# PIC32CX2051MTSH128S1 device description
Architecture: CORTEX-M4; Family: PIC32CXMT; Series: PIC32CXMTSH
Registers are 32-bit, read-write, no defined reset value unless marked. A register's access mark holds for its fields unless they carry their own. Offsets are from the block's base; [hi:lo] are bit positions.

## UART — Universal Asynchronous Receiver Transmitter
Instances: UART 0x48010000
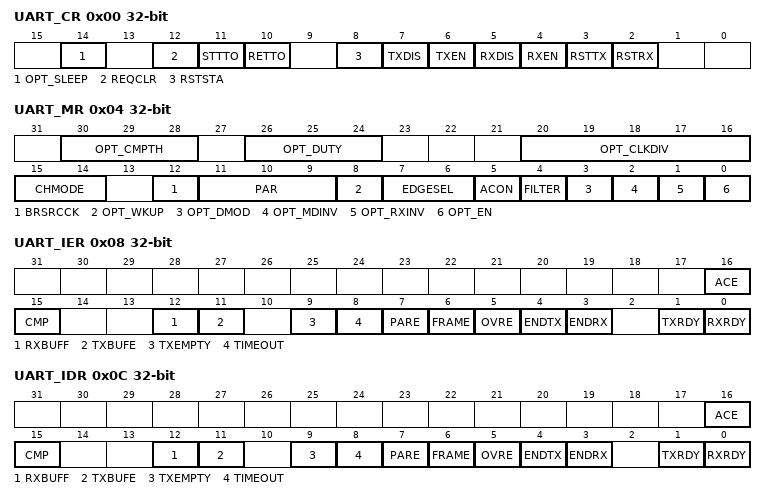
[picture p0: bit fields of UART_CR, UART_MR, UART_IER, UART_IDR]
0x00 UART_CR wo — Control Register
  [14] OPT_SLEEP — Optical Logic Sleep Mode Command
  [12] REQCLR — Request Clear
  [11] STTTO — Start Time-out
  [10] RETTO — Rearm Time-out
  [8] RSTSTA — Reset Status
  [7] TXDIS — Transmitter Disable
  [6] TXEN — Transmitter Enable
  [5] RXDIS — Receiver Disable
  [4] RXEN — Receiver Enable
  [3] RSTTX — Reset Transmitter
  [2] RSTRX — Reset Receiver
0x04 UART_MR — Mode Register
  [30:28] OPT_CMPTH — Receive Path Comparator Threshold
    0=VDD3V3_DIV2 (Comparator threshold is VDD3V3/2 volts.); 1=VDD3V3_DIV2P5 (Comparator threshold is VDD3V3/2.5 volts.); 2=VDD3V3_DIV3P3 (Comparator threshold is VDD3V3/3.3 volts.); 3=VDD3V3_DIV5 (Comparator threshold is VDD3V3/5 volts.); 4=VDD3V3_DIV10 (Comparator threshold is VDD3V3/10 volts.)
  [26:24] OPT_DUTY — Optical Link Modulation Clock Duty Cycle
    0=DUTY_50 (Modulation clock duty cycle Is 50%.); 1=DUTY_43P75 (Modulation clock duty cycle Is 43.75%.); 2=DUTY_37P5 (Modulation clock duty cycle Is 37.5%.); 3=DUTY_31P25 (Modulation clock duty cycle Is 31.75%.); 4=DUTY_25 (Modulation clock duty cycle Is 25%.); 5=DUTY_18P75 (Modulation clock duty cycle Is 18.75%.); 6=DUTY_12P5 (Modulation clock duty cycle Is 12.5%.); 7=DUTY_6P25 (Modulation clock duty cycle Is 6.25%.)
  [20:16] OPT_CLKDIV — Optical Link Clock Divider
  [15:14] CHMODE — Channel Mode
    0=NORMAL (Normal mode); 1=AUTOMATIC (Automatic echo); 2=LOCAL_LOOPBACK; 3=REMOTE_LOOPBACK
  [12] BRSRCCK — Baud Rate Source Clock
    0=PERIPH_CLK (The baud rate is driven by the peripheral clock); 1=GCLK (The baud rate is driven by a PMC-programmable clock GCLK (see the section "Power Management Controller (PMC)").)
  [11:9] PAR — Parity Type
    0=EVEN (Even Parity); 1=ODD (Odd Parity); 2=SPACE (Space: parity forced to 0); 3=MARK (Mark: parity forced to 1); 4=NO (No parity)
  [8] OPT_WKUP — Optical Link Activity Wake-up Enable
    0=DISABLED (To detect any activity on the output of analog comparator, the clock is always active and OPT_EN must be written to 1..); 1=ENABLED (If OPT_EN=0 and a logical 1 is detected after inversion (if RXINV=1) on analog comparator output, the clock if automatically enabled for all UART sub-modules. After a period of inactivity on URXD (time-out) the software can instruct the UART to disabled the clock of all sub-modules to reduce power consumption by applying the UART_CR.OPT_SLEEP command.)
  [7:6] EDGESEL — Analog Comparator Output Edge Selection
    0=RISING (The UART_SR.ACE is set if a rising edge is detected on analog comparator output.); 1=FALLING (The UART_SR.ACE is set if a falling edge is detected on analog comparator output.); 2=ANY_EDGE (The UART_SR.ACE is set as soon as an edge is detected on analog comparator output.)
  [5] ACON — Analog Comparator Enable
    0=DISABLED (The analog comparator is disabled. If OPT_EN=1, the analog comparator is enabled.); 1=ENABLED (The analog comparator is enabled.)
  [4] FILTER — Receiver Digital Filter
    0=DISABLED (UART does not filter the receive line.); 1=ENABLED (UART filters the receive line using a three-sample filter (16x-bit clock) (2 over 3 majority).)
  [3] OPT_DMOD — Optical Demodulation Enable
    0=DISABLED (The optical demodulator is disabled. External demodulation must be enabled.); 1=ENABLED (The optical demodulator is enabled.)
  [2] OPT_MDINV — UART Modulated Data Inverted
    0=DISABLED (The output of the modulator is not inverted.); 1=ENABLED (The output of the modulator is inverted.)
  [1] OPT_RXINV — UART Receive Data Inverted
    0=DISABLED (The comparator data output is not inverted before entering UART.); 1=ENABLED (The comparator data output is inverted before entering UART.)
  [0] OPT_EN — UART Optical Interface Enable
    0=DISABLED (Disables the UART optical link.); 1=ENABLED (Enables the UART optical link.)
0x08 UART_IER wo — Interrupt Enable Register
  [16] ACE — Enable Analog Comparator Event Interrupt
  [15] CMP — Enable Comparison Interrupt
  [12] RXBUFF — Enable Buffer Full Interrupt
  [11] TXBUFE — Enable Buffer Empty Interrupt
  [9] TXEMPTY — Enable TXEMPTY Interrupt
  [8] TIMEOUT — Enable Time-out Interrupt
  [7] PARE — Enable Parity Error Interrupt
  [6] FRAME — Enable Framing Error Interrupt
  [5] OVRE — Enable Overrun Error Interrupt
  [4] ENDTX — Enable End of Transmit Interrupt
  [3] ENDRX — Enable End of Receive Transfer Interrupt
  [1] TXRDY — Enable TXRDY Interrupt
  [0] RXRDY — Enable RXRDY Interrupt
0x0C UART_IDR wo — Interrupt Disable Register
  [16] ACE — Disable Analog Comparator Event Interrupt
  [15] CMP — Disable Comparison Interrupt
  [12] RXBUFF — Disable Buffer Full Interrupt
  [11] TXBUFE — Disable Buffer Empty Interrupt
  [9] TXEMPTY — Disable TXEMPTY Interrupt
  [8] TIMEOUT — Disable Time-out Interrupt
  [7] PARE — Disable Parity Error Interrupt
  [6] FRAME — Disable Framing Error Interrupt
  [5] OVRE — Disable Overrun Error Interrupt
  [4] ENDTX — Disable End of Transmit Interrupt
  [3] ENDRX — Disable End of Receive Transfer Interrupt
  [1] TXRDY — Disable TXRDY Interrupt
  [0] RXRDY — Disable RXRDY Interrupt
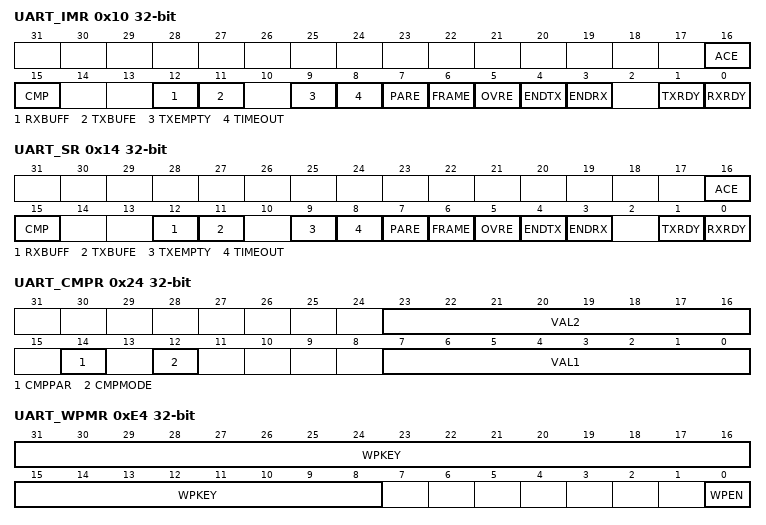
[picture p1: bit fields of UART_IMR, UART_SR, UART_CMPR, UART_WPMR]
0x10 UART_IMR ro — Interrupt Mask Register
  [16] ACE — Mask Analog Comparator Event Interrupt
  [15] CMP — Mask Comparison Interrupt
  [12] RXBUFF — Mask RXBUFF Interrupt
  [11] TXBUFE — Mask TXBUFE Interrupt
  [9] TXEMPTY — Mask TXEMPTY Interrupt
  [8] TIMEOUT — Mask Time-out Interrupt
  [7] PARE — Mask Parity Error Interrupt
  [6] FRAME — Mask Framing Error Interrupt
  [5] OVRE — Mask Overrun Error Interrupt
  [4] ENDTX — Mask End of Transmit Interrupt
  [3] ENDRX — Mask End of Receive Transfer Interrupt
  [1] TXRDY — Mask TXRDY Interrupt
  [0] RXRDY — Mask RXRDY Interrupt
0x14 UART_SR ro — Interrupt Status Register
  [16] ACE — Analog Comparator Event Interrupt (Cleared by writing UART_CR.RSTSTA)
  [15] CMP — Comparison Match (Cleared by writing the UART_CR.RSTSTA)
  [12] RXBUFF — Receive Buffer Full
  [11] TXBUFE — Transmission Buffer Empty
  [9] TXEMPTY — Transmitter Empty (Cleared by writing the UART_THR)
  [8] TIMEOUT — Receiver Time-out (Cleared by writing the UART_CR.STTTO)
  [7] PARE — Parity Error (Cleared by writing UART_CR.RSTSTA)
  [6] FRAME — Framing Error (Cleared by writing UART_CR.RSTSTA)
  [5] OVRE — Overrun Error (Cleared by writing UART_CR.RSTSTA)
  [4] ENDTX — End of Transmitter Transfer
  [3] ENDRX — End of Receiver Transfer
  [1] TXRDY — Transmitter Ready (Cleared by writing the UART_THR)
  [0] RXRDY — Receiver Ready (Cleared by reading the UART_RHR)
0x18 UART_RHR ro — Receive Holding Register
  [7:0] RXCHR — Received Character
0x1C UART_THR wo — Transmit Holding Register
  [7:0] TXCHR — Character to be Transmitted
0x20 UART_BRGR — Baud Rate Generator Register
  [15:0] CD — Clock Divisor
0x24 UART_CMPR — Comparison Register
  [23:16] VAL2 — Second Comparison Value for Received Character
  [14] CMPPAR — Compare Parity
  [12] CMPMODE — Comparison Mode
    0=FLAG_ONLY (Any character is received and comparison function drives CMP flag.); 1=START_CONDITION (Comparison condition must be met to start reception.)
  [7:0] VAL1 — First Comparison Value for Received Character
0x28 UART_RTOR — Receiver Time-out Register
  [7:0] TO — Time-out Value
0x2C UART_CSR ro — Current Status Register
  [0] ACO — Analog Comparator Output
0xE4 UART_WPMR — Write Protection Mode Register
  [31:8] WPKEY — Write Protection Key
    0x554152=PASSWD (Writing any other value in this field aborts the write operation. Always reads as 0.)
  [0] WPEN — Write Protection Enable
0x100 UART_RPR — Receive Pointer Register
  [31:0] RXPTR
0x104 UART_RCR — Receive Counter Register
  [15:0] RXCTR
0x108 UART_TPR — Transmit Pointer Register
  [31:0] TXPTR — Transmit Counter Register
0x10C UART_TCR — Transmit Counter Register
  [15:0] TXCTR
0x110 UART_RNPR — Receive Next Pointer Register
  [31:0] RXNPTR — Receive Next Pointer
0x114 UART_RNCR — Receive Next Counter Register
  [15:0] RXNCTR — Receive Next Counter
0x118 UART_TNPR — Transmit Next Pointer Register
  [31:0] TXNPTR — Transmit Next Pointer
0x11C UART_TNCR — Transmit Next Counter Register
  [15:0] TXNCTR — Transmit Counter Next
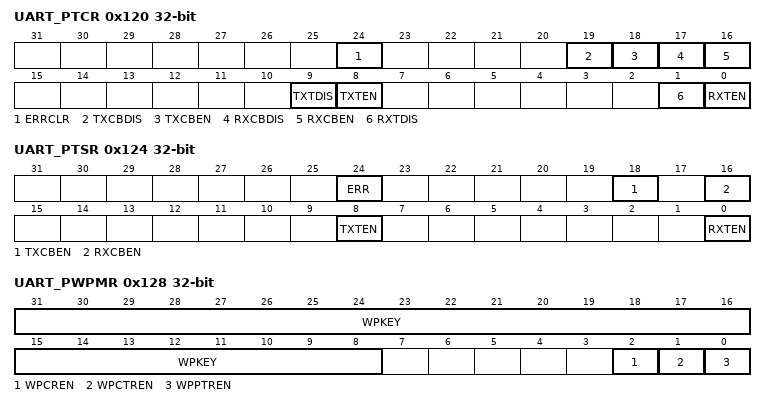
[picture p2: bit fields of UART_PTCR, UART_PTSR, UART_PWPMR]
0x120 UART_PTCR wo — Transfer Control Register
  [24] ERRCLR — Transfer Bus Error Clear
  [19] TXCBDIS — Transmitter Circular Buffer Disable
  [18] TXCBEN — Transmitter Circular Buffer Enable
  [17] RXCBDIS — Receiver Circular Buffer Disable
  [16] RXCBEN — Receiver Circular Buffer Enable
  [9] TXTDIS — Transmitter Transfer Disable
  [8] TXTEN — Transmitter Transfer Enable
  [1] RXTDIS — Receiver Transfer Disable
  [0] RXTEN — Receiver Transfer Enable
0x124 UART_PTSR ro — Transfer Status Register
  [24] ERR — Transfer Bus Error
  [18] TXCBEN — Transmitter Circular Buffer Enable
  [16] RXCBEN — Receiver Circular Buffer Enable
  [8] TXTEN — Transmitter Transfer Enable
  [0] RXTEN — Receiver Transfer Enable
0x128 UART_PWPMR — Write Protection Mode Register
  [31:8] WPKEY — Write Protection Key
    0x504443=PASSWD (Writing any other value in this field aborts the write operation. Always reads as 0.)
  [2] WPCREN — Write Protection Control Register Enable
  [1] WPCTREN — Write Protection Counter Registers Enable
  [0] WPPTREN — Write Protection Pointer Registers Enable
